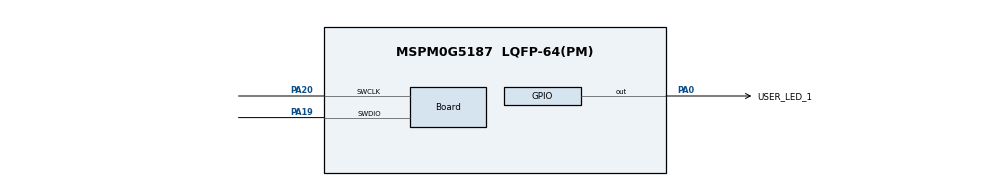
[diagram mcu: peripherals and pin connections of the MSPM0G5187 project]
//@cliArgs --device "MSPM0G518X" --package "LQFP-64(PM)" --part "Default"
//@v2CliArgs --device "MSPM0G5187" --package "LQFP-64(PM)"
// @cliArgs --board /ti/boards/LP_MSPM0G5187 --rtos nortos

/**
 * Import the modules used in this configuration.
 */
const CRCP   = scripting.addModule("/ti/driverlib/CRCP");
const GPIO   = scripting.addModule("/ti/driverlib/GPIO", {}, false);
const GPIO1  = GPIO.addInstance();
const SYSCTL = scripting.addModule("/ti/driverlib/SYSCTL");

/**
 * Write custom configuration values to the imported modules.
 */
CRCP.polynomial                         = "16_POLYNOMIAL_AUG_CCIT";
CRCP.seed                               = 0xF1D;
CRCP.enableCRCCalcWithDMA               = true;
CRCP.endianness                         = "BIG_ENDIAN";
CRCP.DMA_CHANNEL_CRC.$name              = "DMA_CH0";
CRCP.DMA_CHANNEL_CRC.enableInterrupt    = true;
CRCP.DMA_CHANNEL_CRC.srcLength          = "HALF_WORD";
CRCP.DMA_CHANNEL_CRC.dstLength          = "HALF_WORD";
CRCP.DMA_CHANNEL_CRC.peripheral.$assign = "DMA_CH0";

const Board                       = scripting.addModule("/ti/driverlib/Board", {}, false);
Board.peripheral.$assign          = "DEBUGSS";
Board.peripheral.swclkPin.$assign = "PA20";
Board.peripheral.swdioPin.$assign = "PA19";

GPIO1.$name                                 = "GPIO_LEDS";
GPIO1.associatedPins[0].$name               = "USER_LED_1";
GPIO1.associatedPins[0].initialValue        = "SET";
GPIO1.associatedPins[0].assignedPort        = "PORTA";
GPIO1.associatedPins[0].assignedPortSegment = "Lower";
GPIO1.associatedPins[0].assignedPin         = "0";
GPIO1.associatedPins[0].pin.$assign         = "PA0";

SYSCTL.forceDefaultClkConfig = true;
SYSCTL.clockTreeEn           = true;

const ProjectConfig              = scripting.addModule("/ti/project_config/ProjectConfig", {}, false);
ProjectConfig.migrationCondition = true;
